# haltium_secure register map
Vendor: Nordic Semiconductor; Series: nRFHaltium; File version: 1
CPU: CM33 r0p4, little endian, MPU, FPU, 3 interrupt priority bits, 480 interrupts
Registers are 32-bit, read-write, reset 0x0 unless marked. A register's access mark holds for its fields unless they carry their own. Offsets are from the block's base; [hi:lo] are bit positions; lines under a group give offsets from that group; {n}, {i} and the like mark numbered series; 'fields as' and 'values as' point back to an identical list.

## GLOBAL_NFCT_NS — NFC-A compatible radio 0
Base 0x4F985000
Same registers: GLOBAL_NFCT_S 0x5F985000
0x00 TASKS_ACTIVATE wo — Activate NFCT peripheral for incoming and outgoing frames, change state to activated
  [0] TASKS_ACTIVATE
    1=Trigger task
0x04 TASKS_DISABLE wo — Disable NFCT peripheral
  [0] TASKS_DISABLE
    1=Trigger task
0x08 TASKS_SENSE wo — Enable NFC sense field mode, change state to sense mode
  [0] TASKS_SENSE
    1=Trigger task
0x0C TASKS_STARTTX wo — Start transmission of an outgoing frame, change state to transmit
  [0] TASKS_STARTTX
    1=Trigger task
0x10 TASKS_STOPTX wo — Stops an issued transmission of a frame
  [0] TASKS_STOPTX
    1=Trigger task
0x14 TASKS_START_ROSCCAL wo — Starts calibration of ring oscillator
  [0] TASKS_START_ROSCCAL
    1=Trigger task
0x18 TASKS_FREQMEASURE wo — Measures the 13.56 MHz clock frequency
  [0] TASKS_FREQMEASURE
    1=Trigger task
0x1C TASKS_ENABLERXDATA wo — Initializes the EasyDMA for receive.
  [0] TASKS_ENABLERXDATA
    1=Trigger task
0x20 TASKS_DISABLERXDATA wo — Ends current EasyDMA transfer and stops waiting for start of frame (SoF)
  [0] TASKS_DISABLERXDATA
    1=Trigger task
0x24 TASKS_GOIDLE wo — Force state machine to IDLE state
  [0] TASKS_GOIDLE
    1=Trigger task
0x28 TASKS_GOSLEEP wo — Force state machine to SLEEP_A state
  [0] TASKS_GOSLEEP
    1=Trigger task
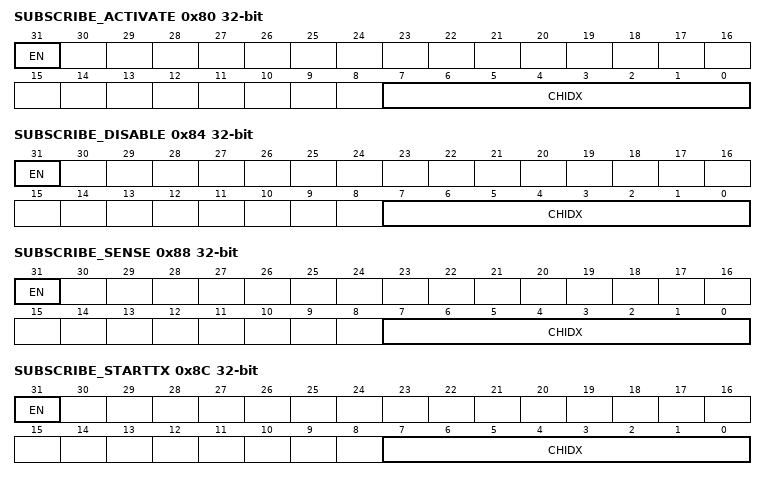
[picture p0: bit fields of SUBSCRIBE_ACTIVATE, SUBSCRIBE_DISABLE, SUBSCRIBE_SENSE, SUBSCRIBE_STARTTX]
0x80 SUBSCRIBE_ACTIVATE — Subscribe configuration for task ACTIVATE
  [31] EN
    0=Disabled (Disable subscription); 1=Enabled (Enable subscription)
  [7:0] CHIDX — DPPI channel that task ACTIVATE will subscribe to
0x84 SUBSCRIBE_DISABLE — Subscribe configuration for task DISABLE
  [31] EN
    values as SUBSCRIBE_ACTIVATE.EN
  [7:0] CHIDX — DPPI channel that task DISABLE will subscribe to
0x88 SUBSCRIBE_SENSE — Subscribe configuration for task SENSE
  [31] EN
    values as SUBSCRIBE_ACTIVATE.EN
  [7:0] CHIDX — DPPI channel that task SENSE will subscribe to
0x8C SUBSCRIBE_STARTTX — Subscribe configuration for task STARTTX
  [31] EN
    values as SUBSCRIBE_ACTIVATE.EN
  [7:0] CHIDX — DPPI channel that task STARTTX will subscribe to
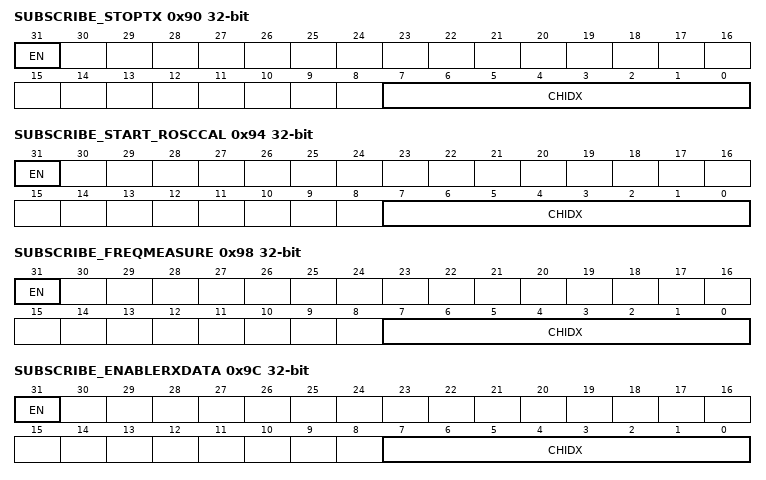
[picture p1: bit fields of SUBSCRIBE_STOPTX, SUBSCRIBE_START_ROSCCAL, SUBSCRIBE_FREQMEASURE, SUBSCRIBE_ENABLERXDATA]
0x90 SUBSCRIBE_STOPTX — Subscribe configuration for task STOPTX
  [31] EN
    values as SUBSCRIBE_ACTIVATE.EN
  [7:0] CHIDX — DPPI channel that task STOPTX will subscribe to
0x94 SUBSCRIBE_START_ROSCCAL — Subscribe configuration for task START_ROSCCAL
  [31] EN
    values as SUBSCRIBE_ACTIVATE.EN
  [7:0] CHIDX — DPPI channel that task START_ROSCCAL will subscribe to
0x98 SUBSCRIBE_FREQMEASURE — Subscribe configuration for task FREQMEASURE
  [31] EN
    values as SUBSCRIBE_ACTIVATE.EN
  [7:0] CHIDX — DPPI channel that task FREQMEASURE will subscribe to
0x9C SUBSCRIBE_ENABLERXDATA — Subscribe configuration for task ENABLERXDATA
  [31] EN
    values as SUBSCRIBE_ACTIVATE.EN
  [7:0] CHIDX — DPPI channel that task ENABLERXDATA will subscribe to
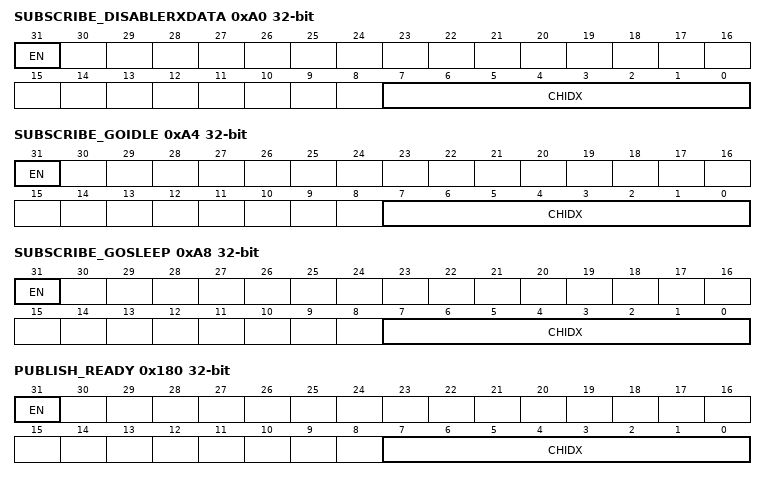
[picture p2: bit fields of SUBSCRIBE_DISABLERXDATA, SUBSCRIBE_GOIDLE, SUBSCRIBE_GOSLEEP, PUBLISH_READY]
0xA0 SUBSCRIBE_DISABLERXDATA — Subscribe configuration for task DISABLERXDATA
  [31] EN
    values as SUBSCRIBE_ACTIVATE.EN
  [7:0] CHIDX — DPPI channel that task DISABLERXDATA will subscribe to
0xA4 SUBSCRIBE_GOIDLE — Subscribe configuration for task GOIDLE
  [31] EN
    values as SUBSCRIBE_ACTIVATE.EN
  [7:0] CHIDX — DPPI channel that task GOIDLE will subscribe to
0xA8 SUBSCRIBE_GOSLEEP — Subscribe configuration for task GOSLEEP
  [31] EN
    values as SUBSCRIBE_ACTIVATE.EN
  [7:0] CHIDX — DPPI channel that task GOSLEEP will subscribe to
0x100 EVENTS_READY — The NFCT peripheral is ready to receive and send frames
  [0] EVENTS_READY
    0=NotGenerated (Event not generated); 1=Generated (Event generated)
0x104 EVENTS_FIELDDETECTED — Remote NFC field detected
  [0] EVENTS_FIELDDETECTED
    values as EVENTS_READY.EVENTS_READY
0x108 EVENTS_FIELDLOST — Remote NFC field lost
  [0] EVENTS_FIELDLOST
    values as EVENTS_READY.EVENTS_READY
0x10C EVENTS_TXFRAMESTART — Marks the start of the first symbol of a transmitted frame
  [0] EVENTS_TXFRAMESTART
    values as EVENTS_READY.EVENTS_READY
0x110 EVENTS_TXFRAMEEND — Marks the end of the last transmitted on-air symbol of a frame data bit on the last positive edge ckTxNfc with nfcTransmit = 1
  [0] EVENTS_TXFRAMEEND
    values as EVENTS_READY.EVENTS_READY
0x114 EVENTS_RXFRAMESTART — Marks the end of the first symbol of a received frame
  [0] EVENTS_RXFRAMESTART
    values as EVENTS_READY.EVENTS_READY
0x118 EVENTS_RXFRAMEEND — Received data has been checked (CRC, parity) and transferred to RAM, and EasyDMA has ended accessing the RX buffer
  [0] EVENTS_RXFRAMEEND
    values as EVENTS_READY.EVENTS_READY
0x11C EVENTS_ERROR — NFC error reported. The ERRORSTATUS register contains details on the source of the error.
  [0] EVENTS_ERROR
    values as EVENTS_READY.EVENTS_READY
0x120 EVENTS_FREQMEASUREDONE — Done with one frequency measurement, result available in the MEASUREDFREQ register. This event will fire several times during calibration.
  [0] EVENTS_FREQMEASUREDONE
    values as EVENTS_READY.EVENTS_READY
0x124 EVENTS_CALCOMPLETE — NFC ring oscillator calibration complete.
  [0] EVENTS_CALCOMPLETE
    values as EVENTS_READY.EVENTS_READY
0x128 EVENTS_RXERROR — NFC RX frame error reported. The FRAMESTATUS.RX register contains details on the source of the error.
  [0] EVENTS_RXERROR
    values as EVENTS_READY.EVENTS_READY
0x12C EVENTS_ENDRX — RX buffer (as defined by PACKETPTR and MAXLEN) in Data RAM full.
  [0] EVENTS_ENDRX
    values as EVENTS_READY.EVENTS_READY
0x130 EVENTS_ENDTX — Transmission of data in RAM has ended, and EasyDMA has ended accessing the TX buffer
  [0] EVENTS_ENDTX
    values as EVENTS_READY.EVENTS_READY
0x138 EVENTS_AUTOCOLRESSTARTED — Auto collision resolution process has started Event generated when ALL_REQ or SENS_REQ has been received while in IDLE state
  [0] EVENTS_AUTOCOLRESSTARTED
    values as EVENTS_READY.EVENTS_READY
{0x138+4i} EVENTS_AUTOCOLRES{i} (i=1..3) — Auto collision resolution cascade level {i} succeeded
  [0] EVENTS_AUTOCOLRES{i}
    values as EVENTS_READY.EVENTS_READY
0x148 EVENTS_COLLISION — NFC auto collision resolution error reported. The AUTOCOLRESSTATUS register contains details on the source of the error.
  [0] EVENTS_COLLISION
    values as EVENTS_READY.EVENTS_READY
0x14C EVENTS_SELECTED — NFC auto collision resolution successfully completed
  [0] EVENTS_SELECTED
    values as EVENTS_READY.EVENTS_READY
0x150 EVENTS_STARTED — EasyDMA is ready to receive or send frames.
  [0] EVENTS_STARTED
    values as EVENTS_READY.EVENTS_READY
0x180 PUBLISH_READY — Publish configuration for event READY
  [31] EN
    0=Disabled (Disable publishing); 1=Enabled (Enable publishing)
  [7:0] CHIDX — DPPI channel that event READY will publish to
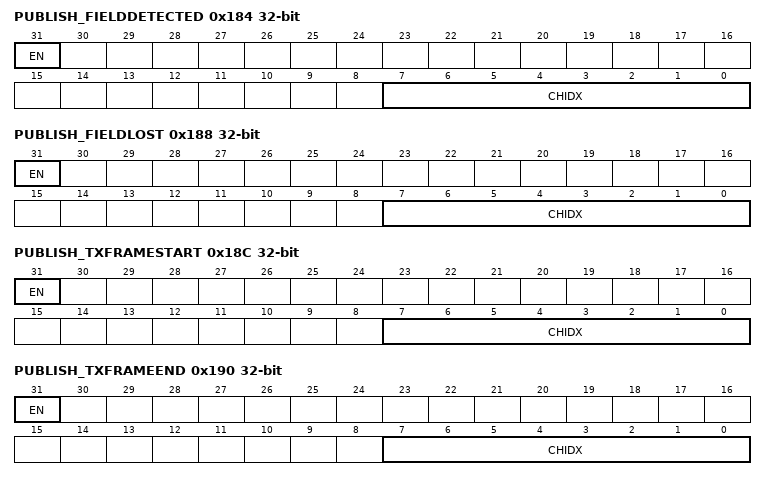
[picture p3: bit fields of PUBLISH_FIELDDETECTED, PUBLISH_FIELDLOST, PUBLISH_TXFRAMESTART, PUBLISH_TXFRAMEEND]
0x184 PUBLISH_FIELDDETECTED — Publish configuration for event FIELDDETECTED
  [31] EN
    values as PUBLISH_READY.EN
  [7:0] CHIDX — DPPI channel that event FIELDDETECTED will publish to
0x188 PUBLISH_FIELDLOST — Publish configuration for event FIELDLOST
  [31] EN
    values as PUBLISH_READY.EN
  [7:0] CHIDX — DPPI channel that event FIELDLOST will publish to
0x18C PUBLISH_TXFRAMESTART — Publish configuration for event TXFRAMESTART
  [31] EN
    values as PUBLISH_READY.EN
  [7:0] CHIDX — DPPI channel that event TXFRAMESTART will publish to
0x190 PUBLISH_TXFRAMEEND — Publish configuration for event TXFRAMEEND
  [31] EN
    values as PUBLISH_READY.EN
  [7:0] CHIDX — DPPI channel that event TXFRAMEEND will publish to
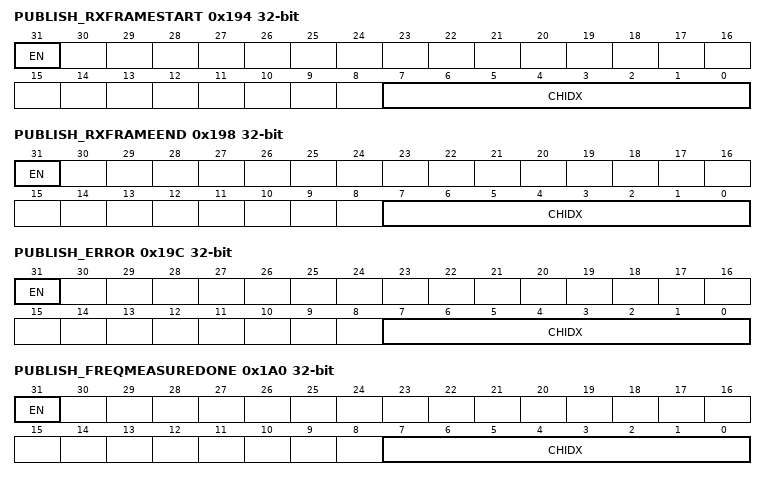
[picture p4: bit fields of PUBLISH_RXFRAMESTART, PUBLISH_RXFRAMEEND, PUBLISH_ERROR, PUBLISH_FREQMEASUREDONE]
0x194 PUBLISH_RXFRAMESTART — Publish configuration for event RXFRAMESTART
  [31] EN
    values as PUBLISH_READY.EN
  [7:0] CHIDX — DPPI channel that event RXFRAMESTART will publish to
0x198 PUBLISH_RXFRAMEEND — Publish configuration for event RXFRAMEEND
  [31] EN
    values as PUBLISH_READY.EN
  [7:0] CHIDX — DPPI channel that event RXFRAMEEND will publish to
0x19C PUBLISH_ERROR — Publish configuration for event ERROR
  [31] EN
    values as PUBLISH_READY.EN
  [7:0] CHIDX — DPPI channel that event ERROR will publish to
0x1A0 PUBLISH_FREQMEASUREDONE — Publish configuration for event FREQMEASUREDONE
  [31] EN
    values as PUBLISH_READY.EN
  [7:0] CHIDX — DPPI channel that event FREQMEASUREDONE will publish to
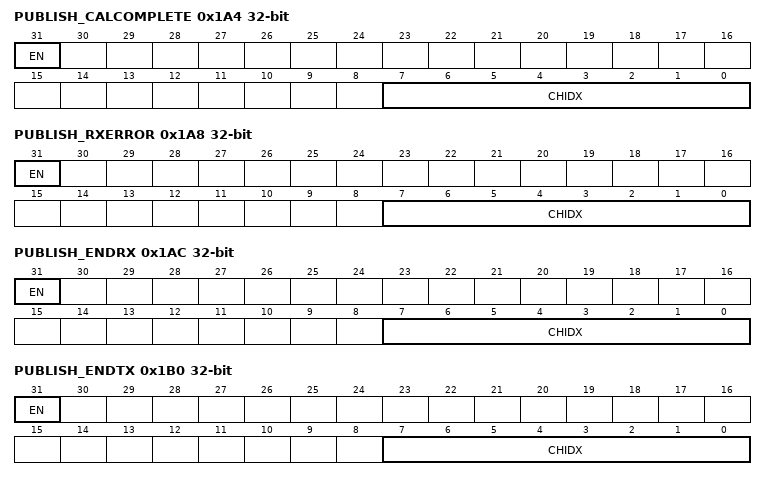
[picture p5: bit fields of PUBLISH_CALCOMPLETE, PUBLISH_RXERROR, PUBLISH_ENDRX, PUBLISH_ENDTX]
0x1A4 PUBLISH_CALCOMPLETE — Publish configuration for event CALCOMPLETE
  [31] EN
    values as PUBLISH_READY.EN
  [7:0] CHIDX — DPPI channel that event CALCOMPLETE will publish to
0x1A8 PUBLISH_RXERROR — Publish configuration for event RXERROR
  [31] EN
    values as PUBLISH_READY.EN
  [7:0] CHIDX — DPPI channel that event RXERROR will publish to
0x1AC PUBLISH_ENDRX — Publish configuration for event ENDRX
  [31] EN
    values as PUBLISH_READY.EN
  [7:0] CHIDX — DPPI channel that event ENDRX will publish to
0x1B0 PUBLISH_ENDTX — Publish configuration for event ENDTX
  [31] EN
    values as PUBLISH_READY.EN
  [7:0] CHIDX — DPPI channel that event ENDTX will publish to
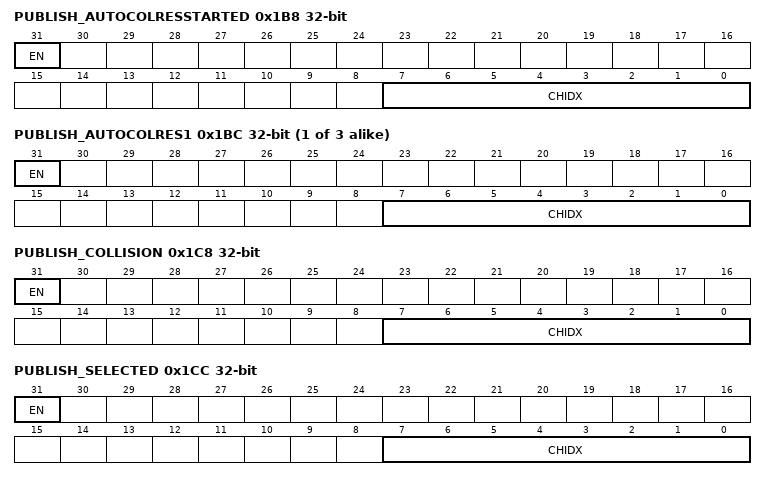
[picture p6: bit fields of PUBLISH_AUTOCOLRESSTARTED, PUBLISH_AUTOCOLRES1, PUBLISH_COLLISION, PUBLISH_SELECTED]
0x1B8 PUBLISH_AUTOCOLRESSTARTED — Publish configuration for event AUTOCOLRESSTARTED
  [31] EN
    values as PUBLISH_READY.EN
  [7:0] CHIDX — DPPI channel that event AUTOCOLRESSTARTED will publish to
{0x1B8+4i} PUBLISH_AUTOCOLRES{i} (i=1..3) — Publish configuration for event AUTOCOLRES{i}
  [31] EN
    values as PUBLISH_READY.EN
  [7:0] CHIDX — DPPI channel that event AUTOCOLRES{i} will publish to
0x1C8 PUBLISH_COLLISION — Publish configuration for event COLLISION
  [31] EN
    values as PUBLISH_READY.EN
  [7:0] CHIDX — DPPI channel that event COLLISION will publish to
0x1CC PUBLISH_SELECTED — Publish configuration for event SELECTED
  [31] EN
    values as PUBLISH_READY.EN
  [7:0] CHIDX — DPPI channel that event SELECTED will publish to
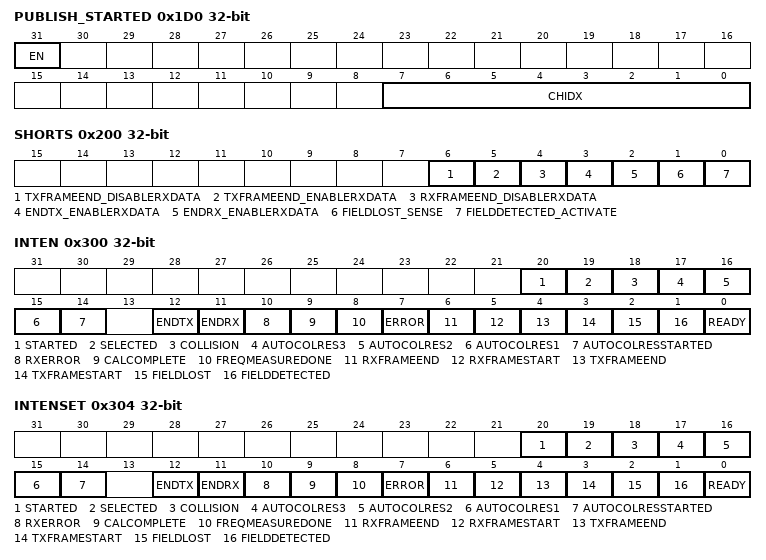
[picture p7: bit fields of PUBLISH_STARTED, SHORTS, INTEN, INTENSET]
0x1D0 PUBLISH_STARTED — Publish configuration for event STARTED
  [31] EN
    values as PUBLISH_READY.EN
  [7:0] CHIDX — DPPI channel that event STARTED will publish to
0x200 SHORTS — Shortcuts between local events and tasks
  [all] fields
    0=Disabled (Disable shortcut); 1=Enabled (Enable shortcut)
  [6] TXFRAMEEND_DISABLERXDATA — Shortcut between event TXFRAMEEND and task DISABLERXDATA
  [5] TXFRAMEEND_ENABLERXDATA — Shortcut between event TXFRAMEEND and task ENABLERXDATA
  [4] RXFRAMEEND_DISABLERXDATA — Shortcut between event RXFRAMEEND and task DISABLERXDATA
  [3] ENDTX_ENABLERXDATA — Shortcut between event ENDTX and task ENABLERXDATA
  [2] ENDRX_ENABLERXDATA — Shortcut between event ENDRX and task ENABLERXDATA
  [1] FIELDLOST_SENSE — Shortcut between event FIELDLOST and task SENSE
  [0] FIELDDETECTED_ACTIVATE — Shortcut between event FIELDDETECTED and task ACTIVATE
0x300 INTEN — Enable or disable interrupt
  [all] fields
    0=Disabled; 1=Enabled
  [20] STARTED — Enable or disable interrupt for event STARTED
  [19] SELECTED — Enable or disable interrupt for event SELECTED
  [18] COLLISION — Enable or disable interrupt for event COLLISION
  [17] AUTOCOLRES3 — Enable or disable interrupt for event AUTOCOLRES3
  [16] AUTOCOLRES2 — Enable or disable interrupt for event AUTOCOLRES2
  [15] AUTOCOLRES1 — Enable or disable interrupt for event AUTOCOLRES1
  [14] AUTOCOLRESSTARTED — Enable or disable interrupt for event AUTOCOLRESSTARTED
  [12] ENDTX — Enable or disable interrupt for event ENDTX
  [11] ENDRX — Enable or disable interrupt for event ENDRX
  [10] RXERROR — Enable or disable interrupt for event RXERROR
  [9] CALCOMPLETE — Enable or disable interrupt for event CALCOMPLETE
  [8] FREQMEASUREDONE — Enable or disable interrupt for event FREQMEASUREDONE
  [7] ERROR — Enable or disable interrupt for event ERROR
  [6] RXFRAMEEND — Enable or disable interrupt for event RXFRAMEEND
  [5] RXFRAMESTART — Enable or disable interrupt for event RXFRAMESTART
  [4] TXFRAMEEND — Enable or disable interrupt for event TXFRAMEEND
  [3] TXFRAMESTART — Enable or disable interrupt for event TXFRAMESTART
  [2] FIELDLOST — Enable or disable interrupt for event FIELDLOST
  [1] FIELDDETECTED — Enable or disable interrupt for event FIELDDETECTED
  [0] READY — Enable or disable interrupt for event READY
0x304 INTENSET — Enable interrupt
  [all] fields
    on read: 0=Disabled (Read: Disabled); 1=Enabled (Read: Enabled) | on write: 1=Set (Enable)
  [20] STARTED — Write '1' to enable interrupt for event STARTED
  [19] SELECTED — Write '1' to enable interrupt for event SELECTED
  [18] COLLISION — Write '1' to enable interrupt for event COLLISION
  [17] AUTOCOLRES3 — Write '1' to enable interrupt for event AUTOCOLRES3
  [16] AUTOCOLRES2 — Write '1' to enable interrupt for event AUTOCOLRES2
  [15] AUTOCOLRES1 — Write '1' to enable interrupt for event AUTOCOLRES1
  [14] AUTOCOLRESSTARTED — Write '1' to enable interrupt for event AUTOCOLRESSTARTED
  [12] ENDTX — Write '1' to enable interrupt for event ENDTX
  [11] ENDRX — Write '1' to enable interrupt for event ENDRX
  [10] RXERROR — Write '1' to enable interrupt for event RXERROR
  [9] CALCOMPLETE — Write '1' to enable interrupt for event CALCOMPLETE
  [8] FREQMEASUREDONE — Write '1' to enable interrupt for event FREQMEASUREDONE
  [7] ERROR — Write '1' to enable interrupt for event ERROR
  [6] RXFRAMEEND — Write '1' to enable interrupt for event RXFRAMEEND
  [5] RXFRAMESTART — Write '1' to enable interrupt for event RXFRAMESTART
  [4] TXFRAMEEND — Write '1' to enable interrupt for event TXFRAMEEND
  [3] TXFRAMESTART — Write '1' to enable interrupt for event TXFRAMESTART
  [2] FIELDLOST — Write '1' to enable interrupt for event FIELDLOST
  [1] FIELDDETECTED — Write '1' to enable interrupt for event FIELDDETECTED
  [0] READY — Write '1' to enable interrupt for event READY
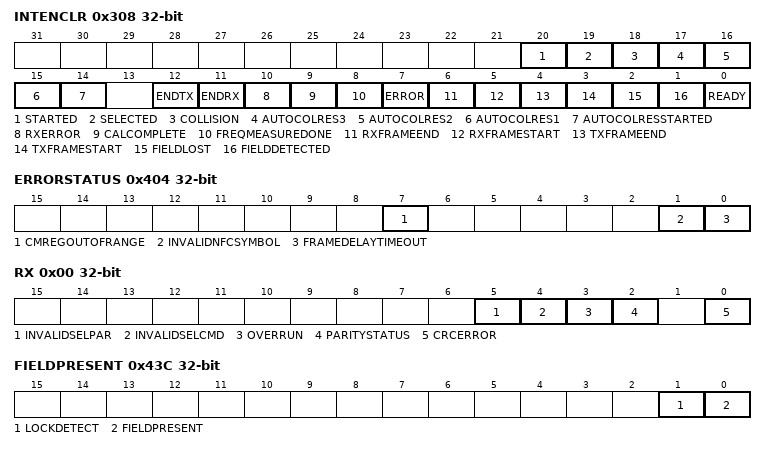
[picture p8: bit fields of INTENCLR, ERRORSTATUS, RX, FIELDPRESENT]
0x308 INTENCLR — Disable interrupt
  [all] fields
    on read: 0=Disabled (Read: Disabled); 1=Enabled (Read: Enabled) | on write: 1=Clear (Disable)
  [20] STARTED — Write '1' to disable interrupt for event STARTED
  [19] SELECTED — Write '1' to disable interrupt for event SELECTED
  [18] COLLISION — Write '1' to disable interrupt for event COLLISION
  [17] AUTOCOLRES3 — Write '1' to disable interrupt for event AUTOCOLRES3
  [16] AUTOCOLRES2 — Write '1' to disable interrupt for event AUTOCOLRES2
  [15] AUTOCOLRES1 — Write '1' to disable interrupt for event AUTOCOLRES1
  [14] AUTOCOLRESSTARTED — Write '1' to disable interrupt for event AUTOCOLRESSTARTED
  [12] ENDTX — Write '1' to disable interrupt for event ENDTX
  [11] ENDRX — Write '1' to disable interrupt for event ENDRX
  [10] RXERROR — Write '1' to disable interrupt for event RXERROR
  [9] CALCOMPLETE — Write '1' to disable interrupt for event CALCOMPLETE
  [8] FREQMEASUREDONE — Write '1' to disable interrupt for event FREQMEASUREDONE
  [7] ERROR — Write '1' to disable interrupt for event ERROR
  [6] RXFRAMEEND — Write '1' to disable interrupt for event RXFRAMEEND
  [5] RXFRAMESTART — Write '1' to disable interrupt for event RXFRAMESTART
  [4] TXFRAMEEND — Write '1' to disable interrupt for event TXFRAMEEND
  [3] TXFRAMESTART — Write '1' to disable interrupt for event TXFRAMESTART
  [2] FIELDLOST — Write '1' to disable interrupt for event FIELDLOST
  [1] FIELDDETECTED — Write '1' to disable interrupt for event FIELDDETECTED
  [0] READY — Write '1' to disable interrupt for event READY
0x400 PWRUPSENSE ro — Tells if the NFCT peripheral is in SENSE mode
  [0] SENSE
    0=Disabled (NFCT is not in SENSE mode); 1=Sense (NFCT is in SENSE mode)
0x404 ERRORSTATUS write-1-clears — NFC Error Status register
  [7] CMREGOUTOFRANGE — Common mode regulation out of range
  [1] INVALIDNFCSYMBOL — Detects any transition on demodulated carrier between 100 RF carrier periods before EoF and 255 RF carrier periods after EoF. This status is cleared on SoF.
  [0] FRAMEDELAYTIMEOUT — No STARTTX task triggered before expiration of the time set in FRAMEDELAYMAX
0x408 AUTOCOLRESSTATUS write-1-clears — NFC Auto collision resolution Error Status register
  [1:0] ERROR — Auto collision resolution status
    0=NoCollision (Auto collision resolution resolved, no error); 1=Cascade1Fail (Auto collision resolution failed at Cascade level 1); 2=Cascade2Fail (Auto collision resolution failed at Cascade level 2); 3=Cascade3Fail (Auto collision resolution failed at Cascade level 3)
0x40C FRAMESTATUS group — Unspecified
  0x00 RX write-1-clears — Result of last incoming frame
    [5] INVALIDSELPAR — Invalid SEL_PAR field of a received SDD_REQ
      0=Valid (No invalid SEL_PAR); 1=Invalid SEL_PAR
    [4] INVALIDSELCMD — Invalid SEL_CMD field of a received SDD_REQ
      0=Valid (No invalid SEL_CMD); 1=Invalid SEL_CMD
    [3] OVERRUN — Overrun detected
      0=No overrun detected; 1=Overrun error
    [2] PARITYSTATUS — Parity status of received frame
      0=ParityOK (Frame received with parity OK); 1=ParityError (Frame received with parity error)
    [0] CRCERROR — No valid end of frame (EoF) detected
      0=CRCCorrect (Valid CRC detected); 1=CRCError (CRC received does not match local check)
0x410 NFCTAGSTATE ro — Current operating state of NFC tag
  [2:0] NFCTAGSTATE
    0=Disabled or sense; 2=RampUp; 3=Idle; 4=Receive; 5=FrameDelay; 6=Transmit
0x420 SLEEPSTATE ro — Sleep state during automatic collision resolution
  [0] SLEEPSTATE — Reflects the sleep state during automatic collision resolution. Set to IDLE by a GOIDLE task. Set to SLEEP_A when a valid SLEEP_REQ frame is received or by a GOSLEEP task.
    0=Idle (State is IDLE.); 1=SleepA (State is SLEEP_A.)
0x424 BYTESWRITTENTORAM ro — Number of bytes written to RAM
  [8:0] BYTESWRITTENTORAM — Number of bytes written to RAM.
0x428 NFCFRAMINGCORESTATE ro
  [2:0] NFCFRAMINGCORESTATE — Current NFC Framing Core State
    0=PadNotConnected (NFC pads not connected); 1=Disabled (NFCT peripheral disabled); 2=Sense (In sense state. But it is transitive state, so visible for one peripheral clock cycle only.); 3=RampUp (NFCT peripheral ramping up); 4=CollisionResolution (Automatic collision resolution in progress); 5=Selected (In selected state); 6=Transmitting (Transmit in progress); 7=Transmit finishing, reading from the RAM buffer completed
0x42C NFCANTICOLRESSTATE — Automatic collision resolution (anti-collision) state
  [3:0] NFCANTICOLRESSTATE — Current Automatic collision resolution (anti-collision) state
    0=IDLE (State IDLE); 1=IDLE_SENS_RES (State IDLE_SENS_RES); 2=READY_A0 (State READY_A0); 3=READY_A0_SEL_RES (State READY_A0_SEL_RES); 4=READY_A0_SDD_RES (State READY_A0_SDD_RES); 5=READY_A1 (State READY_A1); 6=READY_A1_SEL_RES (State READY_A1_SEL_RES); 7=READY_A1_SDD_RES (State READY_A1_SDD_RES); 8=READY_A2 (State READY_A2); 9=READY_A2_SEL_RES (State READY_A2_SEL_RES); 10=READY_A2_SDD_RES (State READY_A2_SDD_RES); 11=ACTIVE_A (State ACTIVE_A); 12=SLEEP_A (State SLEEP_A); 13=SLEEP_A_SENS_RES (State SLEEP_A_SENS_RES)
0x434 MEASUREDFREQ ro — The frequency measured on the 13.56 MHz NFC carrier signal
  [10:0] MEASUREDFREQ — The frequency measured on the 13.56 MHz NFC carrier signal. This result is produced in response to triggering FREQMEASURE. Frequency = 16 MHz * MEASUREDFREQ / 1000
0x438 ROSCCALVALUE ro reset 0xF — The current value used by the ring oscillator
  [4:0] ROSCCALVALUE — The current value used by the ring oscillator. Either given by the calibration engine, or by the override value.
    0=Minimum frequency; 15=Nominal frequency; 31=Maximum frequency
0x43C FIELDPRESENT ro — Indicates the presence or not of a valid field
  [1] LOCKDETECT — Indicates if the low level has locked to the field
    0=Not locked to field; 1=Locked to field
  [0] FIELDPRESENT — Indicates if a valid field is present. Available only in the activated state.
    0=NoField (No valid field detected); 1=FieldPresent (Valid field detected)
0x440 CURRENTPEAKDETECTREF ro — Current peak detect reference
  [2:0] CURRENTPEAKDETECTREF — Current value of peak detect reference voltage adjustment. Same as SHUNTREGCONFIG.PEAKDETECTREFINIT.
    0=1040 mV; 1=1000 mV; 2=960 mV; 3=920 mV; 4=880 mV; 5=840 mV; 6=800 mV; 7=760 mV
0x500 ENABLE — Register to enable NFC functionality
  [0] ENABLE
    0=Disabled (Disable NFC); 1=Enabled (Enable NFC)
0x504 FRAMEDELAYMIN reset 0x480 — Minimum frame delay
  [15:0] FRAMEDELAYMIN — Minimum frame delay in number of 13.56 MHz clocks
0x508 FRAMEDELAYMAX reset 0x1000 — Maximum frame delay
  [19:0] FRAMEDELAYMAX — Maximum frame delay in number of 13.56 MHz clocks
0x50C FRAMEDELAYMODE reset 0x1 — Configuration register for the Frame Delay Timer
  [1:0] FRAMEDELAYMODE
    0=FreeRun (Transmission is independent of frame timer and will start when the STARTTX task is triggered. No timeout.); 1=Window (Frame is transmitted between FRAMEDELAYMIN and FRAMEDELAYMAX); 2=ExactVal (Frame is transmitted exactly at FRAMEDELAYMAX); 3=WindowGrid (Frame is transmitted on a bit grid between FRAMEDELAYMIN and FRAMEDELAYMAX)
0x510 PACKETPTR — Packet pointer for TXD and RXD data storage in Data RAM
  [31:0] PTR — Packet pointer for TXD and RXD data storage in Data RAM. This address is a byte-aligned RAM address.
0x514 MAXLEN — Size of the RAM buffer allocated to TXD and RXD data storage each
  [8:0] MAXLEN
0x518 TXD group — Unspecified
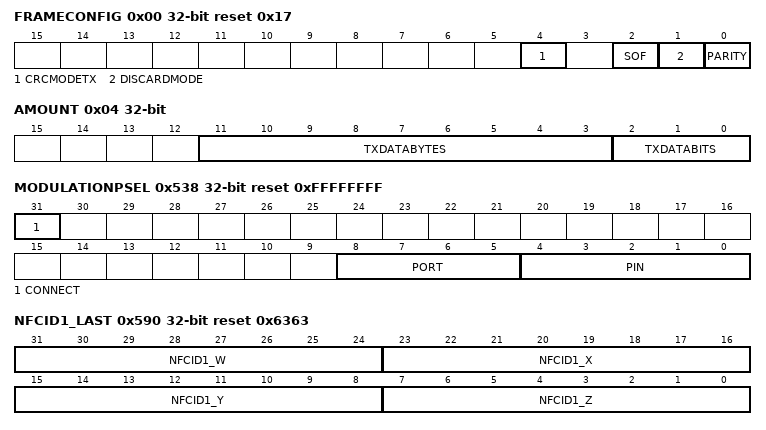
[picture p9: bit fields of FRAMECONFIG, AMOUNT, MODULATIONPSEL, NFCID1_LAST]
  0x00 FRAMECONFIG reset 0x17 — Configuration of outgoing frames
    [4] CRCMODETX — CRC mode for outgoing frames
      0=NoCRCTX (CRC is not added to the frame); 1=CRC16TX (16 bit CRC added to the frame based on all the data read from RAM that is used in the frame)
    [2] SOF — Adding SoF or not in TX frames
      0=NoSoF (SoF symbol not added); 1=SoF (SoF symbol added)
    [1] DISCARDMODE — Discarding unused bits at start or end of a frame
      0=DiscardEnd (Unused bits are discarded at end of frame (EoF)); 1=DiscardStart (Unused bits are discarded at start of frame (SoF))
    [0] PARITY — Indicates if parity is added to the frame
      0=NoParity (Parity is not added to TX frames); 1=Parity is added to TX frames
  0x04 AMOUNT — Size of outgoing frame
    [11:3] TXDATABYTES — Number of complete bytes that shall be included in the frame, excluding CRC, parity, and framing.
    [2:0] TXDATABITS — Number of bits in the last or first byte read from RAM that shall be included in the frame (excluding parity bit).
0x520 RXD group — Unspecified
  0x00 FRAMECONFIG reset 0x15 — Configuration of incoming frames
    [4] CRCMODERX — CRC mode for incoming frames
      0=NoCRCRX (CRC is not expected in RX frames); 1=CRC16RX (Last 16 bits in RX frame is CRC, CRC is checked and CRCSTATUS updated)
    [2] SOF — SoF expected or not in RX frames
      0=NoSoF (SoF symbol is not expected in RX frames); 1=SoF (SoF symbol is expected in RX frames)
    [0] PARITY — Indicates if parity expected in RX frame
      0=NoParity (Parity is not expected in RX frames); 1=Parity is expected in RX frames
  0x04 AMOUNT ro — Size of last incoming frame
    [11:3] RXDATABYTES — Number of complete bytes received in the frame (including CRC, but excluding parity and SoF/EoF framing)
    [2:0] RXDATABITS — Number of bits in the last byte in the frame, if less than 8 (including CRC, but excluding parity and SoF/EoF framing).
0x528 FRAMEDELAYSHIFT reset 0xC — Correction for the frame delay reference
  [3:0] FRAMEDELAYSHIFT — Fine offset for the reference time for frame timing controller counter, measured in carrier frequency periods. Value 8 is no offset. Values greater than 8 means the frame timing controller counter reaches FRAMEDELAYMIN early and values less than 8 means the counter reaches FRAMEDELAYMIN late.
0x52C MODULATIONCTRL reset 0x1 — Enables the modulation output to a GPIO pin which can be connected to a second external antenna.
  [1:0] MODULATIONCTRL — Configuration of modulation control.
    0=Invalid, defaults to same behaviour as for Internal; 1=Internal (Use internal modulator only); 2=ModToGpio (Output digital modulation signal to a GPIO pin.); 3=InternalAndModToGpio (Use internal modulator and output digital modulation signal to a GPIO pin.)
0x530 CRCPOLY reset 0x1021 — CRC polynomial
  [15:0] CRCPOLY — CRC polynomial. Each term in the CRC polynomial is mapped to a bit in this register which index corresponds to the term's exponent. The most significant term (bit 16) is hardwired to 1, and not reflected in the register. The following example is for a 16-bit CRC polynomial: (x16 +) x12 + x5 + 1 = (1) 0001 0000 0010 0001 = 0x1021 (x16 is implicitly 1 and does not need to be written to the register)
0x534 CRCINIT reset 0x6363 — CRC initial value
  [15:0] CRCINIT — Initial value for CRC calculation
    0x6363=NFCA (Initial value for NFC-A); 0xFFFF=NFCBF (Initial value for NFC-B and NFC-F)
0x538 MODULATIONPSEL reset 0xFFFFFFFF — Pin select for Modulation control
  [31] CONNECT — Connection
    1=Disconnected; 0=Connected
  [8:5] PORT — Port number
  [4:0] PIN — Pin number
0x590 NFCID1_LAST reset 0x6363 — Last NFCID1 part (4, 7 or 10 bytes ID)
  [31:24] NFCID1_W — NFCID1 byte W
  [23:16] NFCID1_X — NFCID1 byte X
  [15:8] NFCID1_Y — NFCID1 byte Y
  [7:0] NFCID1_Z — NFCID1 byte Z (very last byte sent)
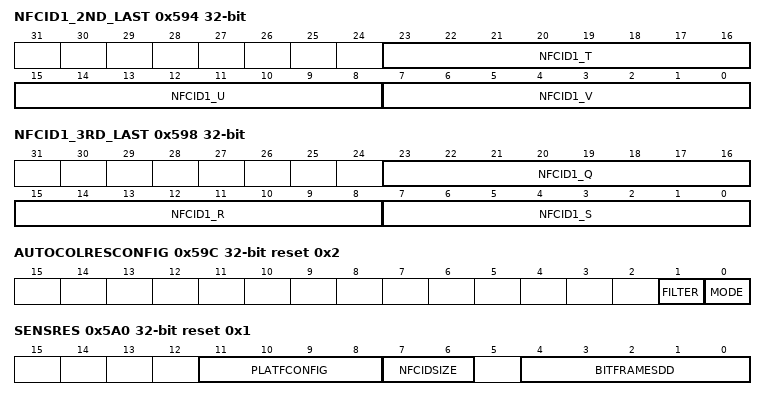
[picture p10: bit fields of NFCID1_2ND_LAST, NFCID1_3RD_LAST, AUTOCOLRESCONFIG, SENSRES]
0x594 NFCID1_2ND_LAST — Second last NFCID1 part (7 or 10 bytes ID)
  [23:16] NFCID1_T — NFCID1 byte T
  [15:8] NFCID1_U — NFCID1 byte U
  [7:0] NFCID1_V — NFCID1 byte V
0x598 NFCID1_3RD_LAST — Third last NFCID1 part (10 bytes ID)
  [23:16] NFCID1_Q — NFCID1 byte Q
  [15:8] NFCID1_R — NFCID1 byte R
  [7:0] NFCID1_S — NFCID1 byte S
0x59C AUTOCOLRESCONFIG reset 0x2 — Controls the auto collision resolution function. This setting must be done before the NFCT peripheral is activated.
  [1] FILTER — Enables/disables auto collision resolution short frame (any frames less than 7 bits) noise filter
    0=Off (Auto collision resolution short frame noise filter disabled); 1=On (Auto collision resolution ignores any frames less than 7 bits)
  [0] MODE — Enables/disables auto collision resolution
    0=Enabled (Auto collision resolution enabled); 1=Disabled (Auto collision resolution disabled)
0x5A0 SENSRES reset 0x1 — NFC-A SENS_RES auto-response settings
  [11:8] PLATFCONFIG — Tag platform configuration as defined by the b4:b1 of byte 2 in SENS_RES response in the NFC Forum, NFC Digital Protocol Technical Specification
  [7:6] NFCIDSIZE — NFCID1 size. This value is used by the auto collision resolution engine.
    0=NFCID1Single (NFCID1 size: single (4 bytes)); 1=NFCID1Double (NFCID1 size: double (7 bytes)); 2=NFCID1Triple (NFCID1 size: triple (10 bytes))
  [4:0] BITFRAMESDD — Bit frame SDD as defined by the b5:b1 of byte 1 in SENS_RES response in the NFC Forum, NFC Digital Protocol Technical Specification
    0=SDD00000 (SDD pattern 00000); 1=SDD00001 (SDD pattern 00001); 2=SDD00010 (SDD pattern 00010); 4=SDD00100 (SDD pattern 00100); 8=SDD01000 (SDD pattern 01000); 16=SDD10000 (SDD pattern 10000)
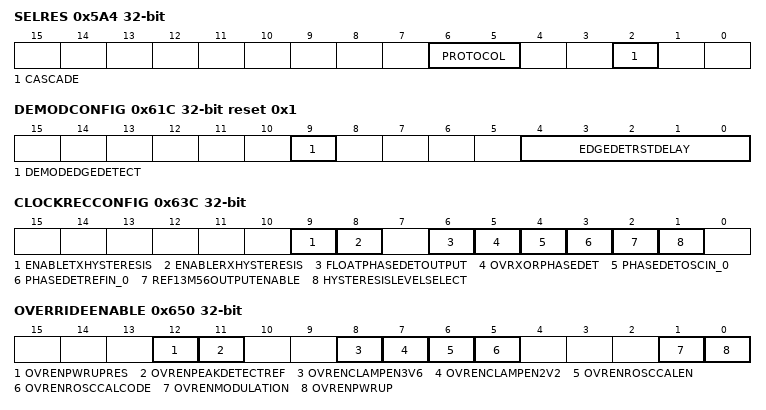
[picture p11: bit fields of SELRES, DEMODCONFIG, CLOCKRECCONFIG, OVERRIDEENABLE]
0x5A4 SELRES — NFC-A SEL_RES auto-response settings
  [6:5] PROTOCOL — Protocol as defined by the b7:b6 of SEL_RES response in the NFC Forum, NFC Digital Protocol Technical Specification
  [2] CASCADE — Cascade as defined by the b3 of SEL_RES response in the NFC Forum, NFC Digital Protocol Technical Specification (controlled by hardware, shall be 0)
0x61C DEMODCONFIG reset 0x1 — Configuration settings for demodulation
  [9] DEMODEDGEDETECT — Selects if an edge detector is enabled to detect the rising edge of an NFC pulse
    0=Disabled (No edge detector - the rising edge of LOCKDETECT or DEMODLEV is used directly); 1=Enabled (Edge detector enabled on the rising edge of the NFC pulse)
  [4:0] EDGEDETRSTDELAY — Time between the falling edge of the NFC pulse and the time when reset is applied, in number of 13.56 MHz clocks
0x620 FIELDDETECTCONFIG reset 0x4 — Configuration for NFCT_FIELDDETECT_TSMC55N
  [2:0] FIELDDETECTLEVEL — Sets the fielddetect level to a value between 0 and 7 (not implemented)
0x624 ANALOGTESTBUSEN — Analog Testbus Enable - ATB0 only
  [2:0] ANALOGTESTBUSEN
    0=TRISTATE; 1=VCOTUNINGVOLTAGE; 2=CMFBOFFSETCOMP (Divided Common mode of NFC1 and NFC2 at the CMFB OFFSET comparator); 3=VREFPEAKDETECTORREF (VREF for peak detector reference); 4=VREFPEAKFORPEAKDET (VREF_PEAK for peak detection); 5=PEAKDETECTOROUTPUT; 6=V2IOUTPUTVOLTAGE (Divided V2I output voltage); 7=INTEGRATOROUTPUT (Divided Integrator output)
0x628 SYMBOLTOLLOWER reset 0x2 — Configuration register for the tolerance of the received NFC pulse width
  [5:0] SYMBOLTOLLOWER — Minimum allowable received NFC pulse width, given in pulses of 13.56 MHz clock
0x62C SYMBOLTOLUPPER reset 0x3F — Configuration register for the tolerance of the received NFC pulse width
  [5:0] SYMBOLTOLUPPER — Maximum allowable received NFC pulse width, given in pulses of 13.56 MHz clock
0x630 CONTINUOUSSUBCARRIER — Selects continuous sub-carrier transmission
  [0] CONTINUOUSSUBCARRIER
    0=Normal modulation; 1=Carrier (Continuous sub-carrier transmission)
0x63C CLOCKRECCONFIG — Configuration for NFCT_CLOCKREC_TSMC55N
  [9] ENABLETXHYSTERESIS — Enables TX hysteresis in the sine-to-square converter
  [8] ENABLERXHYSTERESIS — Enables RX hysteresis in the sine-to-square converter
  [6] FLOATPHASEDETOUTPUT — Set the output of the phase to high-Z
  [5] OVRXORPHASEDET — Override the output of the XOR phase detector to 1
  [4] PHASEDETOSCIN_0 — Sets the oscillator input of the phase detector to 0
  [3] PHASEDETREFIN_0 — Sets the reference input of the phase detector to 0
  [2] REF13M56OUTPUTENABLE — Enables the nfcRef13M56 reference clock output
  [1] HYSTERESISLEVELSELECT — Selects the hysteresis level
0x640 CLOCKSOURCE — Deprecated register - Clock source
  [0] CLOCKSOURCE
    0=Normal mode - Use 13.56 MHz and 16 MHz clocks; 1=16MHz (Use 16 MHz clock only)
0x644 FRAMECONTENT1 — Deprecated register - Buffer for custom-frame autoresponse frame-content, when no DMA is available
  [31:0] FRAMECONTENT1 — Buffer for custom-frame autoresponse (AUTORESPONSEMODE=CustomFrame), when no DMA is available
0x648 FRAMECONTENT2 — Deprecated register - Buffer for custom-frame autoresponse, when no DMA is available
  [31:0] FRAMECONTENT2 — Buffer for custom-frame autoresponse (AUTORESPONSEMODE=CustomFrame), when no DMA is available
0x650 OVERRIDEENABLE — Enables override functionality.
  [12] OVRENPWRUPRES — Override enable for power up resistor in the analog pad. Uses value from OVRVALPWRUPRES.
  [11] OVRENPEAKDETECTREF — Override enable for peak detect reference voltage. Uses value from OVRVALPEAKDETECTREF.
  [8] OVRENCLAMPEN3V6 — Override enable for the 3V6 clamp
  [7] OVRENCLAMPEN2V2 — Override enable for the 2V2 clamp
  [6] OVRENROSCCALEN — Override enable for OVERRIDE_ROSCCALEN
  [5] OVRENROSCCALCODE — Override enable for OVERRIDE_ROSCCALCODE
  [1] OVRENMODULATION — Override enable for modulation on/off
  [0] OVRENPWRUP — Override enable for OVERRIDE_PWRUP
0x660 OVRVALPWRUPNFC — Override value for pwrupNfc
  [1:0] OVRVALPWRUPNFC
0x664 OVRVALMODULATION — Override value for modulation on/off
  [0] OVRVALMODULATION
0x668 OVRVALLOADINACTIVE — Override value for the load control when modulation is off
  [5:0] OVRVALLOADINACTIVE
0x66C OVRVALLOADACTIVE — Override value for the load control when modulation is on
  [5:0] OVRVALLOADACTIVE
0x670 OVRVALPWRUPRES reset 0x1 — Override value for power up resistor in the analog pad
  [0] OVRVALPWRUPRES
0x674 OVRVALROSCCALCODE reset 0xF — Override value for the calibration word for the oscillator
  [4:0] OVRVALROSCCALCODE
0x678 OVRVALROSCCALEN — Override value for the signal CALEN going to the oscillator
  [0] OVRVALROSCCALEN — Override value for the calibration word for the oscillator
0x67C OVRVALCLAMPEN2V2 — Override value for the 2V2 clamp
  [0] OVRVALCLAMPEN2V2
0x680 OVRVALCLAMPEN3V6 — Override value for the 3V6 clamp
  [0] OVRVALCLAMPEN3V6
0x684 AUTOCAL reset 0x1 — Controls auto-calibration at NFCT module enabling
  [0] ROSCEN
    0=Disabled (No auto-calibration at module enablin); 1=Enabled (Enable auto-calibration at module enabling)
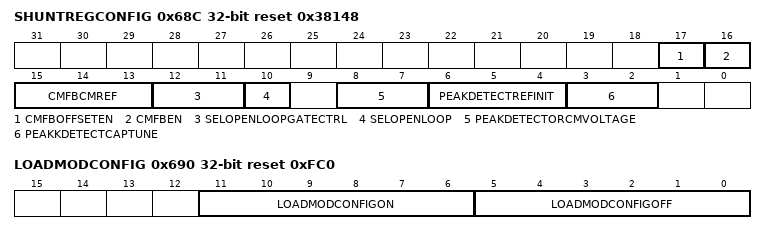
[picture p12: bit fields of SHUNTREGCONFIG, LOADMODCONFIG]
0x68C SHUNTREGCONFIG reset 0x38148 — Configuration for NFCT_SHUNTREG_TSMC55N
  [17] CMFBOFFSETEN — Enable the CMFB offset from the CMFB circuit
    0=Disabled (Feature disabled); 1=Enabled (Feature enabled)
  [16] CMFBEN — Enable CMFB circuit
    0=Disabled (Feature disabled); 1=Enabled (Feature enabled)
  [15:13] CMFBCMREF — Common mode reference for CMFB circuit
    0=0.7 * Vdd; 1=0.65 * Vdd; 2=0.6 * Vdd; 3=0.55 * Vdd; 4=0.5 * Vdd; 5=0.45 * Vdd; 6=0.4 * Vdd; 7=0.35 * Vdd
  [12:11] SELOPENLOOPGATECTRL — Set the gate voltage on shunt NMOS
    0=Vdd; 1=0.75 * Vdd; 2=0.5 * Vdd; 3=0 mV
  [10] SELOPENLOOP — This sets the shunt regulation in open loop mode
    0=SELOPENLOOP_Disabled (Closed loop mode); 1=SELOPENLOOP_Enabled (Open loop mode)
  [8:7] PEAKDETECTORCMVOLTAGE — Peak detector common mode voltage tuning
    0=120 mV; 1=80 mV; 2=40 mV; 3=0 mV
  [6:4] PEAKDETECTREFINIT — Initial peak detect reference value
    values as CURRENTPEAKDETECTREF.CURRENTPEAKDETECTREF
  [3:2] PEAKKDETECTCAPTUNE — Capacitance tuning in peak detection block for swing programmability. The C1 and C2 are coming from, Vpeak-swing = Vref * ((C1 + C2) / C1), Vpeak-swing is NFC swing, Vref is from PEAKDETECTREFINIT
    0=C2=96fF,C1=266fF; 1=C2=116fF,C1=266fF (highest swing); 2=C2=22fF,C1=266fF (lowest swing); 3=C2=52fF,C1=266fF
0x690 LOADMODCONFIG reset 0xFC0 — Configuration for load modulation
  [11:6] LOADMODCONFIGON — Load modulation value when modulation is on
  [5:0] LOADMODCONFIGOFF — Load modulation value when modulation is off. The value has to be 0. Changing it would give undesired results.
0x694 SHUNTNMOSADJUST reset 0x1 — Size adjustment for the shunt NMOS in shunt regulator
  [1:0] SHUNTNMOSADJUST — Size adjustment for shunt NMOS in shunt regulator
0x698 RSHUNTCTRL — Adjust internal shunt resistance
  [2:0] RSHUNTCTRL
0x69C OVRVALPEAKDETECTREF reset 0x4 — Override value for the peak detect reference voltage
  [2:0] OVRVALPEAKDETECTREF
    0=1240 mV; 1=1200 mV; 2=1160 mV; 3=1120 mV; 4=1080 mV; 5=1040 mV; 6=1000 mV; 7=960 mV
0x6A0 LOCKDETECTWINDOW reset 0x4 — Adjust window size on falling edge of lock detect filter used for demodulation
  [2:0] LOCKDETECTWINDOW
